VERSION ""

NS_ :

BS_:

BU_: ADCS_MTQ ADCS_STATEST ADCS_RW_XYZ ADCS_BDot
VAL_TABLE_ ReactionWheelCommand 2 "RW_Cmd_OpenLoop" 1 "RW_Cmd_PID" 0 "RW_Cmd_Stop" ;

BO_ 3221225472 VECTOR__INDEPENDENT_SIG_MSG: 0 Vector__XXX
 SG_ CDH_GroupingID : 0|4@1+ (1,0) [0|15] "" Vector__XXX

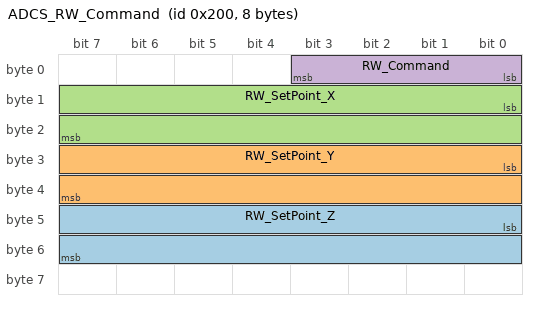
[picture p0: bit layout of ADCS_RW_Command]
BO_ 512 ADCS_RW_Command: 8 ADCS_STATEST
 SG_ RW_SetPoint_Z : 40|16@1- (1,0) [-32768|32767] "rpm"  ADCS_RW_XYZ
 SG_ RW_SetPoint_Y : 24|16@1- (1,0) [-32768|32767] "rpm"  ADCS_RW_XYZ
 SG_ RW_SetPoint_X : 8|16@1- (1,0) [-32768|32767] "rpm"  ADCS_RW_XYZ
 SG_ RW_Command : 0|4@1+ (1,0) [0|2] ""  ADCS_RW_XYZ

CM_ BO_ 3221225472 "This is a message for not used signals, created by Vector CANdb++ DBC OLE DB Provider.";
BA_DEF_  "BusType" STRING ;
BA_DEF_DEF_  "BusType" "CAN";
VAL_ 512 RW_Command 2 "RW_Cmd_OpenLoop" 1 "RW_Cmd_PID" 0 "RW_Cmd_Stop" ;
